# DMASS_DTHE_DMASS_DTHE_DTHE_DTHE_CFG_SM4_WRAP_VBUSP_EIP_12_SM4_40808000h register map
Vendor: Texas Instruments
Peripheral module from a debugger description file (folder am62L).
Registers are 32-bit, write-only, reset 0x0 unless marked. A register's access mark holds for its fields unless they carry their own. Offsets are as the file gives them; lines under a group give offsets from that group; [hi:lo] are bit positions; {n}, {i} and the like mark numbered series; 'fields as' and 'values as' point back to an identical list; <NAME> marks a mode.

## DMASS_DTHE_DTHE_DTHE_CFG_SM4_WRAP_VBUSP_EIP_12_SM4
{0x0+4i} DMASS_DTHE_DTHE_DTHE_CFG_SM4_WRAP_VBUSP_EIP_12_SM4_SM4_DATA_IN_{i} (i=0..3) — Data in register {i}
  [31:0] DATA_IN — Data In [{32i+31}:{32i}]
{0x20+4i} DMASS_DTHE_DTHE_DTHE_CFG_SM4_WRAP_VBUSP_EIP_12_SM4_SM4_KEY_IN_{i} (i=0..3) — Key in register {i}
  [31:0] KEY_IN — Key In [{32i+31}:{32i}]
{0x40+4i} DMASS_DTHE_DTHE_DTHE_CFG_SM4_WRAP_VBUSP_EIP_12_SM4_SM4_PARAM_IN_{i} (i=0..3) — Param in register {i}
  [31:0] PARAM_IN — Param In [{32i+31}:{32i}]
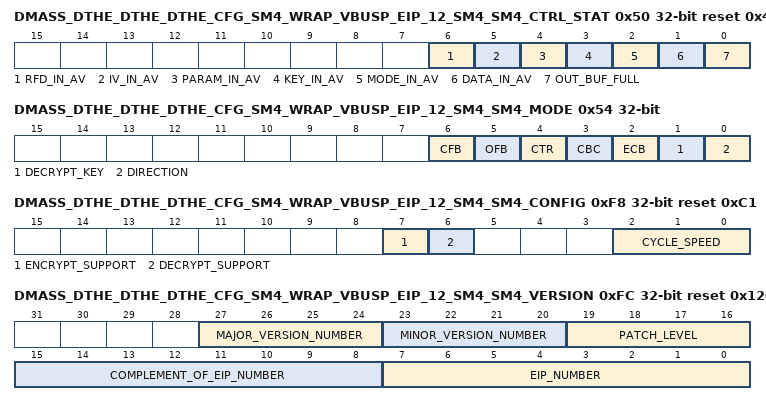
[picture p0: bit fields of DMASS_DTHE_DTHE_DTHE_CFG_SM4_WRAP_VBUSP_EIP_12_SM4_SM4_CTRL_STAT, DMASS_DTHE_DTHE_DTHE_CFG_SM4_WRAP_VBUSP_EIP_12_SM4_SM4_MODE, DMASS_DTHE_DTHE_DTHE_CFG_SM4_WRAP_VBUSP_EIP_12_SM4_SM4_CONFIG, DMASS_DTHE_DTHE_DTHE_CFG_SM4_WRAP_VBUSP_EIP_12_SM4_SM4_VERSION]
0x50 DMASS_DTHE_DTHE_DTHE_CFG_SM4_WRAP_VBUSP_EIP_12_SM4_SM4_CTRL_STAT access not given reset 0x40 — Control Status Register
  [6] RFD_IN_AV ro — RFD in Available
  [5] IV_IN_AV — IV In Available (access R/W1TS)
  [4] PARAM_IN_AV — Param In Available (access R/W1TS)
  [3] KEY_IN_AV — Key In Available (access R/W1TS)
  [2] MODE_IN_AV — Mode In Available (access R/W1TS)
  [1] DATA_IN_AV — Data Input Available (access R/W1TS)
  [0] OUT_BUF_FULL — Output Buffer Full (access R/W1TC)
0x54 DMASS_DTHE_DTHE_DTHE_CFG_SM4_WRAP_VBUSP_EIP_12_SM4_SM4_MODE access per field — Control Status Register
  [6] CFB rw — CFB mode
  [5] OFB rw — OFB mode
  [4] CTR rw — CTR mode
  [3] CBC rw — CBC mode
  [2] ECB rw — ECB mode
  [1] DECRYPT_KEY rw — Decrypt Mode with decrypt key
  [0] DIRECTION rw — Encrypt/Decrypt Mode
{0x58+4i} DMASS_DTHE_DTHE_DTHE_CFG_SM4_WRAP_VBUSP_EIP_12_SM4_SM4_DATA_OUT_{i} ro (i=0..3) — Data Out register {i}
  [31:0] DATA_OUT — Data out [{32i+31}:{32i}]
{0x68+4i} DMASS_DTHE_DTHE_DTHE_CFG_SM4_WRAP_VBUSP_EIP_12_SM4_SM4_IV_IN_OUT_{i} rw (i=0..3) — IV input register {i}. This register can also be read at the last block to save the intermediate IV.
  [31:0] IV — IV In [{32i+31}:{32i}]
0xF8 DMASS_DTHE_DTHE_DTHE_CFG_SM4_WRAP_VBUSP_EIP_12_SM4_SM4_CONFIG ro reset 0xC1 — Hardware Configuration Register
  [7] ENCRYPT_SUPPORT — Support encrypting
  [6] DECRYPT_SUPPORT — Support decrypting
  [2:0] CYCLE_SPEED
0xFC DMASS_DTHE_DTHE_DTHE_CFG_SM4_WRAP_VBUSP_EIP_12_SM4_SM4_VERSION ro reset 0x120F30C — Hardware Version Number
  [27:24] MAJOR_VERSION_NUMBER — Hardware Major Revision
  [23:20] MINOR_VERSION_NUMBER — Hardware Minor Revision
  [19:16] PATCH_LEVEL — Hardware Patch Revision
  [15:8] COMPLEMENT_OF_EIP_NUMBER
  [7:0] EIP_NUMBER
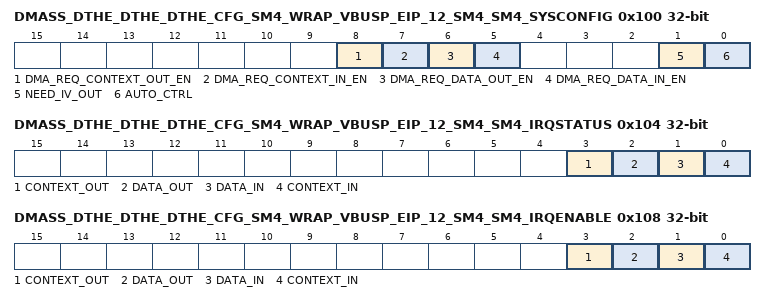
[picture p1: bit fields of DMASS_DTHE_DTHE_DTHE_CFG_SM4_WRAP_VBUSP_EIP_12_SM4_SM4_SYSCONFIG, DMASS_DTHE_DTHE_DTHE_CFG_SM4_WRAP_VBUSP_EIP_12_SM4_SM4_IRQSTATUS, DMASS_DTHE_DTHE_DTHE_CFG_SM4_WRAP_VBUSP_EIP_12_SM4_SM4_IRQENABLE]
0x100 DMASS_DTHE_DTHE_DTHE_CFG_SM4_WRAP_VBUSP_EIP_12_SM4_SM4_SYSCONFIG rw — Enable register for the different dma request lines and the automatic trigger of the core.
  [8] DMA_REQ_CONTEXT_OUT_EN — Enable DMA request for IV output.
  [7] DMA_REQ_CONTEXT_IN_EN — Enable DMA request for context input.
  [6] DMA_REQ_DATA_OUT_EN — Enable DMA request for data output.
  [5] DMA_REQ_DATA_IN_EN — Enable DMA request for data input.
  [1] NEED_IV_OUT — Flag to indicate if IV_OUT is desired to determine when buffer can be cleared. This field is only useful when auto_ctrl is enabled and the cipher is non ECB mode.
  [0] AUTO_CTRL — Turn on mode where HW can automatically issue dma request and/or interrupt. When set to 1, dma requests or sm4_intr will assert to request new push or pop of data. If set to 0, SW will need to commit the inputs manually through Writing/Reading/polling the bits in the SM4_CTRL_STAT register. There is no dma request or interrupt when the auto_ctrl is 0.
0x104 DMASS_DTHE_DTHE_DTHE_CFG_SM4_WRAP_VBUSP_EIP_12_SM4_SM4_IRQSTATUS rw — contains the raw status of each interrupt source
  [3] CONTEXT_OUT — When set to 1, indicates the 16 bytes of IV is available from the IV output registers.
  [2] DATA_OUT — When set to 1, indicates the 16 bytes of data is available from the data output registers.
  [1] DATA_IN — When set to 1, indicates the data buffer is ready to receive the next 16 bytes of data block.
  [0] CONTEXT_IN — When set to 1, indicates that the context input register is available for new context for the next packet.
0x108 DMASS_DTHE_DTHE_DTHE_CFG_SM4_WRAP_VBUSP_EIP_12_SM4_SM4_IRQENABLE rw — contains an enable bit for each unique source for the sm4_intr output. This enable is independent of the dma request. The auto_ctrl in SYSCONFIG must be set to 1 for interrupt to be generated.
  [3] CONTEXT_OUT — Context Out Interrupt Enable. Set to 1 if sm4_intr should be asserted when there is IV out request.
  [2] DATA_OUT — Data Out Interrupt Enable. Set to 1 if sm4_intr should be asserted when there is new data out request.
  [1] DATA_IN — Data In Interrupt Enable. Set to 1 if sm4_intr should be asserted when there is new data in request.
  [0] CONTEXT_IN — Context In Interrupt Enable. Set to 1 if sm4_intr should be asserted when there is new context in request.
0x10C DMASS_DTHE_DTHE_DTHE_CFG_SM4_WRAP_VBUSP_EIP_12_SM4_SM4_LENGTH rw — Input data length register in unit of bytes
  [31:0] LENGTH — Data length in bytes for all supported SM4 modes. Length should be multiple of 16 bytes. Once processing with this context is started the length decrements by 16
